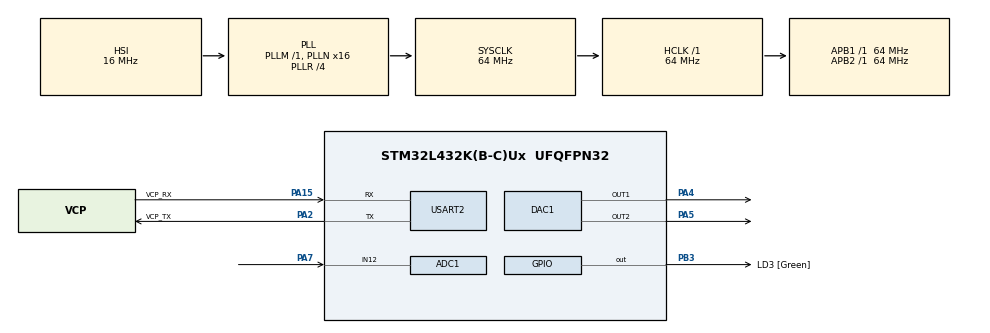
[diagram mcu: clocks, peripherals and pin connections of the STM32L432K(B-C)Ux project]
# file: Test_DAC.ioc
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ADC1.AWD1HighThreshold=0x80
ADC1.AWD1ITMode=ENABLE
ADC1.AWD1LowThreshold=0x40
ADC1.Channel-1\#ChannelRegularConversion=ADC_CHANNEL_12
ADC1.ContinuousConvMode=ENABLE
ADC1.EnableAnalogWatchDog1=true
ADC1.NbrOfConversionFlag=1
ADC1.OffsetNumber-1\#ChannelRegularConversion=ADC_OFFSET_NONE
ADC1.Rank-1\#ChannelRegularConversion=1
ADC1.SamplingTime-1\#ChannelRegularConversion=ADC_SAMPLETIME_2CYCLES_5
ADC1.WatchdogChannel=ADC_CHANNEL_12
ADC1.master=1
DAC1.DAC_Channel-DAC_OUT2=DAC_CHANNEL_2
Mcu.Family=STM32L4
Mcu.Name=STM32L432K(B-C)Ux
Mcu.Package=UFQFPN32
NVIC.ADC1_IRQn=true\:0\:0\:false\:false\:true\:true\:true\:true
NVIC.PriorityGroup=NVIC_PRIORITYGROUP_4
PA0.GPIO_Label=MCO [High speed clock in]
PA0.Mode=HSE-External-Clock-Source-for-LittleOrca
PA0.Signal=RCC_CK_IN
PA13\ (JTMS-SWDIO).GPIO_Label=SWDIO
PA13\ (JTMS-SWDIO).Mode=Serial_Wire
PA13\ (JTMS-SWDIO).Signal=SYS_JTMS-SWDIO
PA14\ (JTCK-SWCLK).GPIO_Label=SWCLK
PA14\ (JTCK-SWCLK).Mode=Serial_Wire
PA14\ (JTCK-SWCLK).Signal=SYS_JTCK-SWCLK
PA15\ (JTDI).GPIO_Label=VCP_RX
PA15\ (JTDI).Mode=Asynchronous
PA15\ (JTDI).Signal=USART2_RX
PA2.GPIO_Label=VCP_TX
PA2.Mode=Asynchronous
PA2.Signal=USART2_TX
PA4.Signal=COMP_DAC11_group
PA5.Signal=COMP_DAC12_group
PA7.Signal=ADCx_IN12
PB3\ (JTDO-TRACESWO).GPIO_Label=LD3 [Green]
PB3\ (JTDO-TRACESWO).Signal=GPIO_Output
PC14-OSC32_IN\ (PC14).Mode=LSE-External-Oscillator
PC14-OSC32_IN\ (PC14).Signal=RCC_OSC32_IN
PC15-OSC32_OUT\ (PC15).Mode=LSE-External-Oscillator
PC15-OSC32_OUT\ (PC15).Signal=RCC_OSC32_OUT
ProjectManager.HeapSize=0x200
ProjectManager.StackSize=0x400
ProjectManager.TargetToolchain=STM32CubeIDE
RCC.ADCFreq_Value=64000000
RCC.AHBFreq_Value=64000000
RCC.APB1Freq_Value=64000000
RCC.APB1TimFreq_Value=64000000
RCC.APB2Freq_Value=64000000
RCC.APB2TimFreq_Value=64000000
RCC.CortexFreq_Value=64000000
RCC.HCLKFreq_Value=64000000
RCC.HSE_VALUE=8000000
RCC.HSI16_VALUE=16000000
RCC.HSI48_VALUE=48000000
RCC.HSI_VALUE=16000000
RCC.MSI_VALUE=4000000
RCC.PLLMUL=RCC_PLLMUL_4
RCC.PLLN=16
RCC.PLLR=RCC_PLLR_DIV4
RCC.PLLSourceVirtual=RCC_PLLSOURCE_HSI
RCC.SYSCLKFreq_VALUE=64000000
RCC.SYSCLKSource=RCC_SYSCLKSOURCE_PLLCLK
RCC.USBFreq_Value=64000000
RCC.VCOOutputFreq_Value=256000000
SH.ADCx_IN12.0=ADC1_IN12,IN12-Single-Ended
SH.COMP_DAC11_group.0=DAC1_OUT1,DAC_OUT1
SH.COMP_DAC12_group.0=DAC1_OUT2,DAC_OUT2
USART2.VirtualMode-Asynchronous=VM_ASYNC
board=NUCLEO-L432KC

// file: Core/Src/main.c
/* USER CODE BEGIN Header */
/**
  ******************************************************************************
  * @file           : main.c
  * @brief          : Main program body
  ******************************************************************************
  * @attention
  *
  * Copyright (c) 2024 STMicroelectronics.
  * All rights reserved.
  *
  * This software is licensed under terms that can be found in the LICENSE file
  * in the root directory of this software component.
  * If no LICENSE file comes with this software, it is provided AS-IS.
  *
  ******************************************************************************
  */
/* USER CODE END Header */
#include "main.h"

ADC_HandleTypeDef hadc1;

DAC_HandleTypeDef hdac1;

UART_HandleTypeDef huart2;

/* USER CODE BEGIN PV */
volatile uint16_t val_dac1, val_dac2=0;

/* USER CODE END PV */

void SystemClock_Config(void);
static void MX_GPIO_Init(void);
static void MX_USART2_UART_Init(void);
static void MX_DAC1_Init(void);
static void MX_ADC1_Init(void);

int main(void)
{

  /* MCU Configuration--------------------------------------------------------*/

  /* Reset of all peripherals, Initializes the Flash interface and the Systick. */
  HAL_Init();

  /* Configure the system clock */
  SystemClock_Config();

  /* Initialize all configured peripherals */
  MX_GPIO_Init();
  MX_USART2_UART_Init();
  MX_DAC1_Init();
  MX_ADC1_Init();
  /* USER CODE BEGIN 2 */
  HAL_DAC_Start(&hdac1, DAC_CHANNEL_1);
  HAL_DAC_Start(&hdac1, DAC_CHANNEL_2);
  /* USER CODE END 2 */

  /* Infinite loop */
  /* USER CODE BEGIN WHILE */
  while (1)
  {
	  HAL_Delay(1000);

	  HAL_DAC_SetValue(&hdac1, DAC_CHANNEL_1, DAC_ALIGN_12B_R, val_dac1);
	  HAL_DAC_SetValue(&hdac1, DAC_CHANNEL_2, DAC_ALIGN_12B_R, val_dac2);

    /* USER CODE END WHILE */

  }
}

void SystemClock_Config(void)
{
  RCC_OscInitTypeDef RCC_OscInitStruct = {0};
  RCC_ClkInitTypeDef RCC_ClkInitStruct = {0};

  /** Configure the main internal regulator output voltage
  */
  if (HAL_PWREx_ControlVoltageScaling(PWR_REGULATOR_VOLTAGE_SCALE1) != HAL_OK)
  {
    Error_Handler();
  }

  /** Initializes the RCC Oscillators according to the specified parameters
  * in the RCC_OscInitTypeDef structure.
  */
  RCC_OscInitStruct.OscillatorType = RCC_OSCILLATORTYPE_HSI;
  RCC_OscInitStruct.HSIState = RCC_HSI_ON;
  RCC_OscInitStruct.HSICalibrationValue = RCC_HSICALIBRATION_DEFAULT;
  RCC_OscInitStruct.PLL.PLLState = RCC_PLL_ON;
  RCC_OscInitStruct.PLL.PLLSource = RCC_PLLSOURCE_HSI;
  RCC_OscInitStruct.PLL.PLLM = 1;
  RCC_OscInitStruct.PLL.PLLN = 16;
  RCC_OscInitStruct.PLL.PLLP = RCC_PLLP_DIV7;
  RCC_OscInitStruct.PLL.PLLQ = RCC_PLLQ_DIV2;
  RCC_OscInitStruct.PLL.PLLR = RCC_PLLR_DIV4;
  if (HAL_RCC_OscConfig(&RCC_OscInitStruct) != HAL_OK)
  {
    Error_Handler();
  }

  /** Initializes the CPU, AHB and APB buses clocks
  */
  RCC_ClkInitStruct.ClockType = RCC_CLOCKTYPE_HCLK|RCC_CLOCKTYPE_SYSCLK
                              |RCC_CLOCKTYPE_PCLK1|RCC_CLOCKTYPE_PCLK2;
  RCC_ClkInitStruct.SYSCLKSource = RCC_SYSCLKSOURCE_PLLCLK;
  RCC_ClkInitStruct.AHBCLKDivider = RCC_SYSCLK_DIV1;
  RCC_ClkInitStruct.APB1CLKDivider = RCC_HCLK_DIV1;
  RCC_ClkInitStruct.APB2CLKDivider = RCC_HCLK_DIV1;

  if (HAL_RCC_ClockConfig(&RCC_ClkInitStruct, FLASH_LATENCY_3) != HAL_OK)
  {
    Error_Handler();
  }
}

static void MX_ADC1_Init(void)
{

  ADC_AnalogWDGConfTypeDef AnalogWDGConfig = {0};
  ADC_ChannelConfTypeDef sConfig = {0};

  /** Common config
  */
  hadc1.Instance = ADC1;
  hadc1.Init.ClockPrescaler = ADC_CLOCK_ASYNC_DIV1;
  hadc1.Init.Resolution = ADC_RESOLUTION_12B;
  hadc1.Init.DataAlign = ADC_DATAALIGN_RIGHT;
  hadc1.Init.ScanConvMode = ADC_SCAN_DISABLE;
  hadc1.Init.EOCSelection = ADC_EOC_SINGLE_CONV;
  hadc1.Init.LowPowerAutoWait = DISABLE;
  hadc1.Init.ContinuousConvMode = ENABLE;
  hadc1.Init.NbrOfConversion = 1;
  hadc1.Init.DiscontinuousConvMode = DISABLE;
  hadc1.Init.ExternalTrigConv = ADC_SOFTWARE_START;
  hadc1.Init.ExternalTrigConvEdge = ADC_EXTERNALTRIGCONVEDGE_NONE;
  hadc1.Init.DMAContinuousRequests = DISABLE;
  hadc1.Init.Overrun = ADC_OVR_DATA_PRESERVED;
  hadc1.Init.OversamplingMode = DISABLE;
  if (HAL_ADC_Init(&hadc1) != HAL_OK)
  {
    Error_Handler();
  }

  /** Configure Analog WatchDog 1
  */
  AnalogWDGConfig.WatchdogNumber = ADC_ANALOGWATCHDOG_1;
  AnalogWDGConfig.WatchdogMode = ADC_ANALOGWATCHDOG_SINGLE_REG;
  AnalogWDGConfig.Channel = ADC_CHANNEL_12;
  AnalogWDGConfig.ITMode = ENABLE;
  AnalogWDGConfig.HighThreshold = 0x80;
  AnalogWDGConfig.LowThreshold = 0x40;
  if (HAL_ADC_AnalogWDGConfig(&hadc1, &AnalogWDGConfig) != HAL_OK)
  {
    Error_Handler();
  }

  /** Configure Regular Channel
  */
  sConfig.Channel = ADC_CHANNEL_12;
  sConfig.Rank = ADC_REGULAR_RANK_1;
  sConfig.SamplingTime = ADC_SAMPLETIME_2CYCLES_5;
  sConfig.SingleDiff = ADC_SINGLE_ENDED;
  sConfig.OffsetNumber = ADC_OFFSET_NONE;
  sConfig.Offset = 0;
  if (HAL_ADC_ConfigChannel(&hadc1, &sConfig) != HAL_OK)
  {
    Error_Handler();
  }

}

static void MX_DAC1_Init(void)
{

  /* USER CODE BEGIN DAC1_Init 0 */
  GPIO_InitTypeDef          GPIO_InitStruct = {0};
  /* USER CODE END DAC1_Init 0 */

  DAC_ChannelConfTypeDef sConfig = {0};

  /* USER CODE BEGIN DAC1_Init 1 */
  /*##-2- Configure peripheral GPIO ##########################################*/
  /* DAC Channel1 GPIO pin configuration */
  __HAL_RCC_GPIOA_CLK_ENABLE();
  GPIO_InitStruct.Pin = GPIO_PIN_4|GPIO_PIN_5;
  GPIO_InitStruct.Mode = GPIO_MODE_ANALOG;
  GPIO_InitStruct.Pull = GPIO_NOPULL;

  HAL_GPIO_Init(GPIOA, &GPIO_InitStruct);
  /* USER CODE END DAC1_Init 1 */

  /** DAC Initialization
  */
  hdac1.Instance = DAC1;
  if (HAL_DAC_Init(&hdac1) != HAL_OK)
  {
    Error_Handler();
  }

  /** DAC channel OUT1 config
  */
  sConfig.DAC_SampleAndHold = DAC_SAMPLEANDHOLD_DISABLE;
  sConfig.DAC_Trigger = DAC_TRIGGER_NONE;
  sConfig.DAC_OutputBuffer = DAC_OUTPUTBUFFER_ENABLE;
  sConfig.DAC_ConnectOnChipPeripheral = DAC_CHIPCONNECT_DISABLE;
  sConfig.DAC_UserTrimming = DAC_TRIMMING_FACTORY;
  if (HAL_DAC_ConfigChannel(&hdac1, &sConfig, DAC_CHANNEL_1) != HAL_OK)
  {
    Error_Handler();
  }

  /** DAC channel OUT2 config
  */
  if (HAL_DAC_ConfigChannel(&hdac1, &sConfig, DAC_CHANNEL_2) != HAL_OK)
  {
    Error_Handler();
  }

}

static void MX_USART2_UART_Init(void)
{

  huart2.Instance = USART2;
  huart2.Init.BaudRate = 115200;
  huart2.Init.WordLength = UART_WORDLENGTH_8B;
  huart2.Init.StopBits = UART_STOPBITS_1;
  huart2.Init.Parity = UART_PARITY_NONE;
  huart2.Init.Mode = UART_MODE_TX_RX;
  huart2.Init.HwFlowCtl = UART_HWCONTROL_NONE;
  huart2.Init.OverSampling = UART_OVERSAMPLING_16;
  huart2.Init.OneBitSampling = UART_ONE_BIT_SAMPLE_DISABLE;
  huart2.AdvancedInit.AdvFeatureInit = UART_ADVFEATURE_NO_INIT;
  if (HAL_UART_Init(&huart2) != HAL_OK)
  {
    Error_Handler();
  }

}

static void MX_GPIO_Init(void)
{
  GPIO_InitTypeDef GPIO_InitStruct = {0};

  /* GPIO Ports Clock Enable */
  __HAL_RCC_GPIOC_CLK_ENABLE();
  __HAL_RCC_GPIOA_CLK_ENABLE();
  __HAL_RCC_GPIOB_CLK_ENABLE();

  /*Configure GPIO pin Output Level */
  HAL_GPIO_WritePin(LD3_GPIO_Port, LD3_Pin, GPIO_PIN_RESET);

  /*Configure GPIO pin : LD3_Pin */
  GPIO_InitStruct.Pin = LD3_Pin;
  GPIO_InitStruct.Mode = GPIO_MODE_OUTPUT_PP;
  GPIO_InitStruct.Pull = GPIO_NOPULL;
  GPIO_InitStruct.Speed = GPIO_SPEED_FREQ_LOW;
  HAL_GPIO_Init(LD3_GPIO_Port, &GPIO_InitStruct);

}

void Error_Handler(void)
{
  __disable_irq();
  while (1)
  {
  }
}
